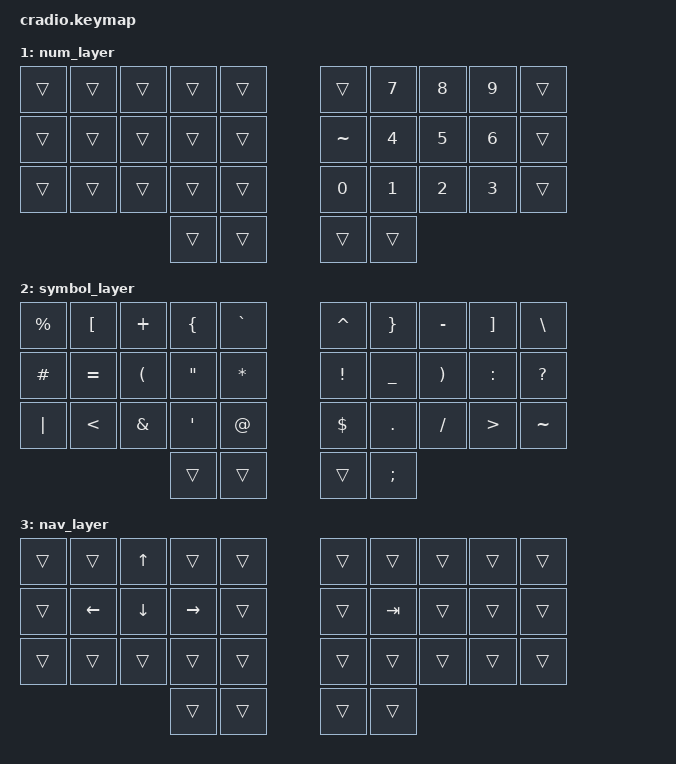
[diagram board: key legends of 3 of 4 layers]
// Copyright (c) 2022 The ZMK Contributors
// SPDX-License-Identifier: MIT

#include <behaviors.dtsi>
#include <dt-bindings/zmk/keys.h>
#include <dt-bindings/zmk/bt.h>

// Home row mods macro
#define HRML(k1,k2,k3,k4) &ht LSHFT k1  &ht LALT k2  &ht LCTRL k3  &ht LGUI k4
#define HRMR(k1,k2,k3,k4) &ht RGUI k1  &ht RCTRL k2  &ht RALT k3  &ht RSHFT k4
#define DEFAULT 0
#define NUM 1
#define SYM 2
#define NAV 3

/ {
    behaviors {
        ht: hold_tap {
            compatible = "zmk,behavior-hold-tap";
            #binding-cells = <2>;
            flavor = "tap-preferred";
            tapping-term-ms = <220>;
            quick-tap-ms = <150>;
            require-prior-idle-ms = <100>;
            bindings = <&kp>, <&kp>;
        };
    };

    keymap {
        compatible = "zmk,keymap";
        default_layer {
            bindings = <
        //╭──────────┬──────────┬──────────┬──────────┬──────────╮   ╭──────────┬──────────┬──────────┬──────────┬──────────╮
        //│  Q       │  W       │  E       │  R       │  T       │   │  Y       │  U       │  I       │  O       │  P       │
            &kp W      &kp L      &kp R      &kp B      &kp Z          &kp SQT     &kp Q      &kp U      &kp D      &kp J
        //├──────────┼──────────┼──────────┼──────────┼──────────┤   ├──────────┼──────────┼──────────┼──────────┼──────────┤
        //│  A       │  S       │  D       │  F       │  G       │   │  H       │  J       │  K       │  L       │ ' "      │
            HRML(S,        H,         N,         T)     &kp COMMA       &kp DOT     HRMR(A,        E,         O,        I)
        //├──────────┼──────────┼──────────┼──────────┼──────────┤   ├──────────┼──────────┼──────────┼──────────┼──────────┤
        //│  Z       │  X       │  C       │  V       │  B       │   │  N       │  M       │ , <      │ . >      │ / ?      │
            &kp F      &kp M      &kp V      &kp C      &mo NUM         &kp G      &kp P      &kp X      &kp K    &kp Y
        //╰──────────┴──────────┴──────────┼──────────┼──────────┤   ├──────────┼──────────┼──────────┴──────────┴──────────╯
                                            &mo SYM     &kp ENTER     &kp BSPC  &lt NAV SPACE
        //                                 ╰──────────┴──────────╯   ╰──────────┴──────────╯
            >;
        };

        num_layer {
            bindings = <
        //╭──────────┬──────────┬──────────┬──────────┬──────────╮   ╭──────────┬──────────┬──────────┬──────────┬──────────╮
        //│          │  [       │  {       │  }       │          │   │  ^       │  (       │  )       │  ]       │  ~       │
            &trans     &trans       &trans    &trans     &trans         &trans      &kp N7      &kp N8  &kp N9     &trans
        //├──────────┼──────────┼──────────┼──────────┼──────────┤   ├──────────┼──────────┼──────────┼──────────┼──────────┤
        //│  !       │  @       │  #       │  $       │  %       │   │  *       │  -       │  =       │  \       │  `       │
            &trans      &trans      &trans    &trans    &trans        &kp TILDE   &kp N4     &kp N5     &kp N6    &trans
        //├──────────┼──────────┼──────────┼──────────┼──────────┤   ├──────────┼──────────┼──────────┼──────────┼──────────┤
        //│          │          │          │          │          │   │  &       │  _       │  +       │  │       │          │
            &trans     &trans     &trans     &trans     &trans         &kp N0      &kp N1      &kp N2   &kp N3     &trans
        //╰──────────┴──────────┴──────────┼──────────┼──────────┤   ├──────────┼──────────┼──────────┴──────────┴──────────╯
                                             &trans     &trans         &trans     &trans
        //                                 ╰──────────┴──────────╯   ╰──────────┴──────────╯
            >;
        };
        symbol_layer {
            bindings = <
        //╭──────────┬──────────┬──────────┬──────────┬──────────╮   ╭──────────┬──────────┬──────────┬──────────┬──────────╮
        //│     %    │  [       │  +       │  {       │     `    │   │  ^       │  }       │  -       │  ]       │  \       │
            &kp PRCNT   &kp LBKT  &kp PLUS    &kp LBRC   &kp GRAVE      &kp CARET &kp RBRC  &kp MINUS  &kp RBKT    &kp BSLH
        //├──────────┼──────────┼──────────┼──────────┼──────────┤   ├──────────┼──────────┼──────────┼──────────┼──────────┤
        //│  \#      │  =       │  (       │  "       │  *       │   │  !       │  _       │  )       │  :       │  ?       │
            &kp HASH  &kp EQUAL   &kp LPAR    &kp DQT   &kp STAR        &kp EXCL  &kp UNDER &kp RPAR   &kp COLON  &kp QMARK
        //├──────────┼──────────┼──────────┼──────────┼──────────┤   ├──────────┼──────────┼──────────┼──────────┼──────────┤
        //│    |     │    <     │     &    │     '    │    @     │   │  $       │  .       │  /       │  >       │    ~     │
            &kp PIPE    &kp LT     &kp AMPS   &kp SQT  &kp AT         &kp DLLR   &kp DOT    &kp FSLH    &kp GT    &kp TILDE
        //╰──────────┴──────────┴──────────┼──────────┼──────────┤   ├──────────┼──────────┼──────────┴──────────┴──────────╯
                                             &trans     &trans         &trans     &kp SEMI
        //                                 ╰──────────┴──────────╯   ╰──────────┴──────────╯
            >;
        };
        nav_layer {
            bindings = <
        //╭──────────┬──────────┬──────────┬──────────┬──────────╮   ╭──────────┬──────────┬──────────┬──────────┬──────────╮
        //│          │  [       │  {       │  }       │          │   │  ^       │  (       │  )       │  ]       │  ~       │
            &trans     &trans       &kp UP    &trans     &trans         &trans      &trans      &trans  &trans     &trans
        //├──────────┼──────────┼──────────┼──────────┼──────────┤   ├──────────┼──────────┼──────────┼──────────┼──────────┤
        //│  !       │  @       │  #       │  $       │  %       │   │  *       │  -       │  =       │  \       │  `       │
            &trans     &kp LEFT   &kp DOWN   &kp RIGHT   &trans         &trans     &kp TAB     &trans     &trans    &trans
        //├──────────┼──────────┼──────────┼──────────┼──────────┤   ├──────────┼──────────┼──────────┼──────────┼──────────┤
        //│          │          │          │          │          │   │  &       │  _       │  +       │  │       │          │
            &trans     &trans     &trans     &trans     &trans         &trans      &trans      &trans   &trans     &trans
        //╰──────────┴──────────┴──────────┼──────────┼──────────┤   ├──────────┼──────────┼──────────┴──────────┴──────────╯
                                             &trans     &trans         &trans     &trans
        //                                 ╰──────────┴──────────╯   ╰──────────┴──────────╯
            >;
        };
       
    };
};
/*

 trans_layer {
            bindings = <
        //╭──────────┬──────────┬──────────┬──────────┬──────────╮   ╭──────────┬──────────┬──────────┬──────────┬──────────╮
        //│          │  [       │  {       │  }       │          │   │  ^       │  (       │  )       │  ]       │  ~       │
            &trans     &trans       &trans    &trans     &trans         &trans      &trans      &trans  &trans     &trans
        //├──────────┼──────────┼──────────┼──────────┼──────────┤   ├──────────┼──────────┼──────────┼──────────┼──────────┤
        //│  !       │  @       │  #       │  $       │  %       │   │  *       │  -       │  =       │  \       │  `       │
            &trans      &trans      &trans    &trans    &trans         &trans   &trans     &trans     &trans    &trans
        //├──────────┼──────────┼──────────┼──────────┼──────────┤   ├──────────┼──────────┼──────────┼──────────┼──────────┤
        //│          │          │          │          │          │   │  &       │  _       │  +       │  │       │          │
            &trans     &trans     &trans     &trans     &trans         &trans      &trans      &trans   &trans     &trans
        //╰──────────┴──────────┴──────────┼──────────┼──────────┤   ├──────────┼──────────┼──────────┴──────────┴──────────╯
                                             &trans     &trans         &trans     &trans
        //                                 ╰──────────┴──────────╯   ╰──────────┴──────────╯
            >;
        };

*/
